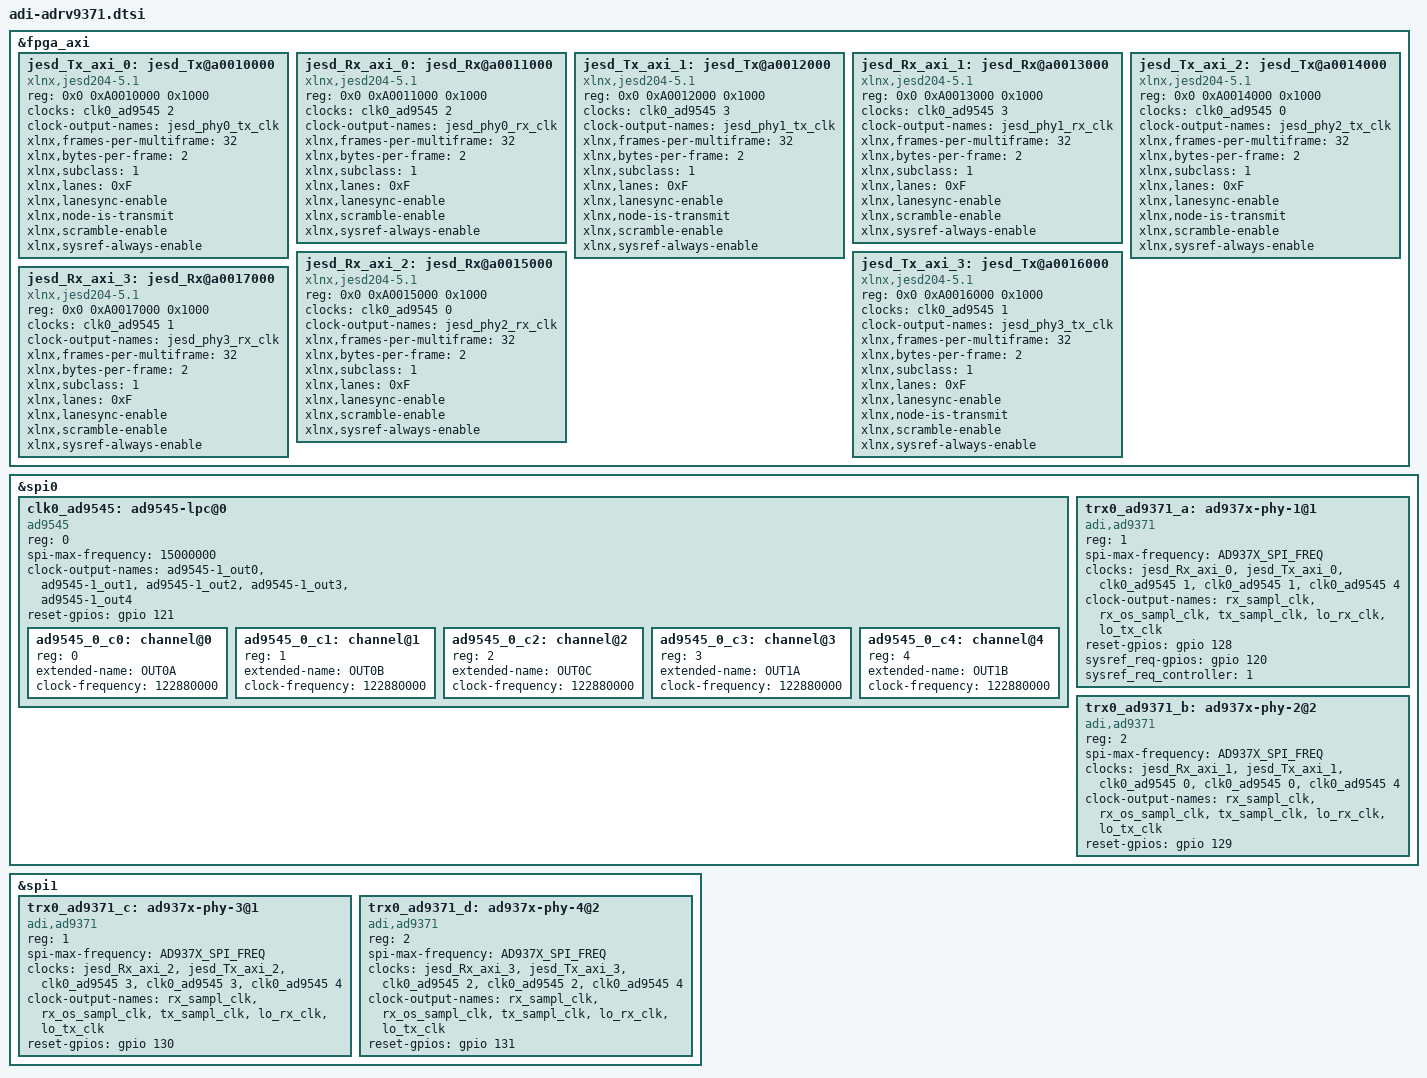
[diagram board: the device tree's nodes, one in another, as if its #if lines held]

#include <dt-bindings/iio/frequency/ad9528.h>

//#define USE_AD9545DRV_CFG_AD9528

&fpga_axi {
	//------------------------------
	//           1st
	//------------------------------
	// TO AD9371_A S1_REFCLKP  9528_C_13
	jesd_Tx_axi_0: jesd_Tx@a0010000 {
		#clock-cells = <0>;
		compatible = "xlnx,jesd204-5.1";
		reg = <0x0 0xA0010000 0x1000>;

#ifdef USE_AD9545DRV_CFG_AD9528
		clocks = <&clk0_ad9545 2>;
#else
		clocks = <&clk0_ad9528 4>;
#endif
		clock-names = "jesd_clk";
		clock-output-names = "jesd_phy0_tx_clk";

		xlnx,frames-per-multiframe = <32>;
		xlnx,bytes-per-frame = <2>;
		xlnx,subclass = <1>;
		xlnx,lanes = <0xF>;
		xlnx,lanesync-enable;
		xlnx,node-is-transmit;

		xlnx,scramble-enable;
		xlnx,sysref-always-enable;
	};
	jesd_Rx_axi_0: jesd_Rx@a0011000 {
		#clock-cells = <0>;
		compatible = "xlnx,jesd204-5.1";
		reg = <0x0 0xA0011000 0x1000>;

#ifdef USE_AD9545DRV_CFG_AD9528
		clocks = <&clk0_ad9545 2>;
#else
		clocks = <&clk0_ad9528 4>;
#endif
		clock-names = "jesd_clk";
		clock-output-names = "jesd_phy0_rx_clk";

		xlnx,frames-per-multiframe = <32>;
		xlnx,bytes-per-frame = <2>;
		xlnx,subclass = <1>;
		xlnx,lanes = <0xF>;
		xlnx,lanesync-enable;

		xlnx,scramble-enable;
		xlnx,sysref-always-enable;
	} ;
	//------------------------------
	//           2nd
	//------------------------------
	// TO AD9371_A S2_REFCLKP  9528_C_10
	jesd_Tx_axi_1: jesd_Tx@a0012000 {
		#clock-cells = <0>;
		compatible = "xlnx,jesd204-5.1";
		reg = <0x0 0xA0012000 0x1000>;

#ifdef USE_AD9545DRV_CFG_AD9528
		clocks = <&clk0_ad9545 3>;
#else
		clocks = <&clk0_ad9528 6>;
#endif
		clock-names = "jesd_clk";
		clock-output-names = "jesd_phy1_tx_clk";

		xlnx,frames-per-multiframe = <32>;
		xlnx,bytes-per-frame = <2>;
		xlnx,subclass = <1>;
		xlnx,lanes = <0xF>;
		xlnx,lanesync-enable;
		xlnx,node-is-transmit;

		xlnx,scramble-enable;
		xlnx,sysref-always-enable;
	};
	jesd_Rx_axi_1: jesd_Rx@a0013000 {
		#clock-cells = <0>;
		compatible = "xlnx,jesd204-5.1";
		reg = <0x0 0xA0013000 0x1000>;

#ifdef USE_AD9545DRV_CFG_AD9528
		clocks = <&clk0_ad9545 3>;
#else
		clocks = <&clk0_ad9528 6>;
#endif
		clock-names = "jesd_clk";
		clock-output-names = "jesd_phy1_rx_clk";

		xlnx,frames-per-multiframe = <32>;
		xlnx,bytes-per-frame = <2>;
		xlnx,subclass = <1>;
		xlnx,lanes = <0xF>;
		xlnx,lanesync-enable;

		xlnx,scramble-enable;
		xlnx,sysref-always-enable;
	} ;

	//------------------------------
	//           3rd
	//------------------------------
	// TO AD9371_C S3_REFCLKP  9528_C_8
	jesd_Tx_axi_2: jesd_Tx@a0014000 {
		#clock-cells = <0>;
		compatible = "xlnx,jesd204-5.1";
		reg = <0x0 0xA0014000 0x1000>;

#ifdef USE_AD9545DRV_CFG_AD9528
		clocks = <&clk0_ad9545 0>;
#else
		clocks = <&clk0_ad9528 1>;
#endif
		clock-names = "jesd_clk";
		clock-output-names = "jesd_phy2_tx_clk";

		xlnx,frames-per-multiframe = <32>;
		xlnx,bytes-per-frame = <2>;
		xlnx,subclass = <1>;
		xlnx,lanes = <0xF>;
		xlnx,lanesync-enable;
		xlnx,node-is-transmit;

		xlnx,scramble-enable;
		xlnx,sysref-always-enable;
	};
	jesd_Rx_axi_2: jesd_Rx@a0015000 {
		#clock-cells = <0>;
		compatible = "xlnx,jesd204-5.1";
		reg = <0x0 0xA0015000 0x1000>;

#ifdef USE_AD9545DRV_CFG_AD9528
		clocks = <&clk0_ad9545 0>;
#else
		clocks = <&clk0_ad9528 1>;
#endif
		clock-names = "jesd_clk";
		clock-output-names = "jesd_phy2_rx_clk";

		xlnx,frames-per-multiframe = <32>;
		xlnx,bytes-per-frame = <2>;
		xlnx,subclass = <1>;
		xlnx,lanes = <0xF>;
		xlnx,lanesync-enable;

		xlnx,scramble-enable;
		xlnx,sysref-always-enable;
	} ;
	//------------------------------
	//           4th
	//------------------------------
	// TO AD9371_D S3_REFCLKP  9528_C_8
	jesd_Tx_axi_3: jesd_Tx@a0016000 {
		#clock-cells = <0>;
		compatible = "xlnx,jesd204-5.1";
		reg = <0x0 0xA0016000 0x1000>;

#ifdef USE_AD9545DRV_CFG_AD9528
		clocks = <&clk0_ad9545 1>;
#else
		clocks = <&clk0_ad9528 3>;
#endif
		clock-names = "jesd_clk";
		clock-output-names = "jesd_phy3_tx_clk";

		xlnx,frames-per-multiframe = <32>;
		xlnx,bytes-per-frame = <2>;
		xlnx,subclass = <1>;
		xlnx,lanes = <0xF>;
		xlnx,lanesync-enable;
		xlnx,node-is-transmit;

		xlnx,scramble-enable;
		xlnx,sysref-always-enable;
	};
	jesd_Rx_axi_3: jesd_Rx@a0017000 {
		#clock-cells = <0>;
		compatible = "xlnx,jesd204-5.1";
		reg = <0x0 0xA0017000 0x1000>;

#ifdef USE_AD9545DRV_CFG_AD9528
		clocks = <&clk0_ad9545 1>;
#else
		clocks = <&clk0_ad9528 3>;
#endif
		clock-names = "jesd_clk";
		clock-output-names = "jesd_phy3_rx_clk";

		xlnx,frames-per-multiframe = <32>;
		xlnx,bytes-per-frame = <2>;
		xlnx,subclass = <1>;
		xlnx,lanes = <0xF>;
		xlnx,lanesync-enable;

		xlnx,scramble-enable;
		xlnx,sysref-always-enable;
	} ;

};

#define AD937X_SPI_FREQ 15000000

&spi0 {

#ifdef USE_AD9545DRV_CFG_AD9528
	/* 用9545的驱动按刷寄存器列表的方式初始化9528 */

	clk0_ad9545: ad9545-lpc@0 {
			#address-cells = <1>;
			#size-cells = <0>;
			#clock-cells = <1>;
			compatible = "ad9545";
			reg = <0>;

			//spi-3wire;
			spi-max-frequency = <15000000>;

			//reset-gpios = <&gpio_daq1 3 0>;

			clock-output-names = "ad9545-1_out0", "ad9545-1_out1", "ad9545-1_out2", "ad9545-1_out3", "ad9545-1_out4";

/include/ "ad9545map.dtsi"

			ad9545_0_c0:channel@0 {
				reg = <0>;
				extended-name = "OUT0A";
				clock-frequency = <122880000>;
			};
			ad9545_0_c1:channel@1 {
				reg = <1>;
				extended-name = "OUT0B";
				clock-frequency = <122880000>;

			};
			ad9545_0_c2:channel@2 {
				reg = <2>;
				extended-name = "OUT0C";
				clock-frequency = <122880000>;

			};
			ad9545_0_c3:channel@3 {
				reg = <3>;
				extended-name = "OUT1A";
				clock-frequency = <122880000>;

			};
			ad9545_0_c4:channel@4 {
				reg = <4>;
				extended-name = "OUT1B";
				clock-frequency = <122880000>;

			};
	};

#else		/* 用9545的驱动按刷寄存器列表的方式初始化9528 */

	clk0_ad9528: ad9528-1@0 {
			#address-cells = <1>;
			#size-cells = <0>;
			#clock-cells = <1>;
			compatible = "ad9528";

			spi-max-frequency = <15000000>;
			//adi,spi-3wire-enable;
			reg = <0>;

			clock-output-names = "ad9528-1_out0", "ad9528-1_out1", "ad9528-1_out2", "ad9528-1_out3", "ad9528-1_out4", "ad9528-1_out5", 	"ad9528-1_out6", "ad9528-1_out7", "ad9528-1_out8", "ad9528-1_out9", "ad9528-1_out10", "ad9528-1_out11", "ad9528-1_out12", 	"ad9528-1_out13";
#if defined (OSC_122M88)
			adi,vcxo-freq = <122880000>;
#elif defined (OSC_30M72)
			adi,vcxo-freq = <30720000>;
#endif
			adi,refa-enable=<1>;	// rj
			adi,refa-diff-rcv-enable=<1>;	//rj

#if defined (OSC_122M88)
            adi,refa-r-div = <8>;	// rj <32>;
#elif defined (OSC_30M72)
			adi,refa-r-div = <128>;
#endif
			//adi,osc-in-cmos-neg-inp-enable;

			adi,refb-r-div = <16>;	// rj

			/* PLL1 config */
			adi,pll1-feedback-div = <64>;	// <256>;

			adi,pll1-charge-pump-current-nA = <63500>;


			/* PLL2 config */
			adi,pll2-ndiv-a-cnt = <0>;
			adi,pll2-ndiv-b-cnt = <30>;
			adi,pll2-vco-diff-m1 = <3>; /* use 5 for 184320000 output device clock */
#if defined (OSC_122M88)
						adi,pll2-n2-div = <10>; /* N / M1 */
#elif defined (OSC_30M72)
						adi,pll2-n2-div = <40>; /* N / M1 */
#endif
			adi,pll2-r1-div = <1>;
			adi,pll2-charge-pump-current-nA = <805000>;

			adi,ref-mode=<REF_MODE_SELECT_REFB>;	// rj

			/* SYSREF config */
			adi,sysref-src = <SYSREF_SRC_INTERNAL>;
			adi,sysref-pattern-mode = <SYSREF_PATTERN_CONTINUOUS>;
			adi,sysref-k-div = <512>;
			adi,sysref-request-enable;
			adi,sysref-nshot-mode = <SYSREF_NSHOT_4_PULSES>;
			adi,sysref-request-trigger-mode = <SYSREF_LEVEL_HIGH>;

			adi,rpole2 = <RPOLE2_900_OHM>;
			adi,rzero = <RZERO_1850_OHM>;
			adi,cpole1 = <CPOLE1_16_PF>;

			adi,status-mon-pin0-function-select = <1>; /* PLL1 & PLL2 Locked */
			adi,status-mon-pin1-function-select = <7>; /* REFA Correct */

			ad9528_0_c0: channel@0 {
				reg = <0>;
				adi,extended-name = "C_AD9373_SYSREFCLK";
				adi,driver-mode = <DRIVER_MODE_LVDS>;
				adi,divider-phase = <0>;
				adi,channel-divider = <10>;
				adi,signal-source = <SOURCE_SYSREF_VCO>;
			};

			ad9528_0_c1: channel@1 {
				reg = <1>;
				adi,extended-name = "C_AD9373_DEVCLK";
				adi,driver-mode = <DRIVER_MODE_LVDS>;
				adi,divider-phase = <0>;
				adi,channel-divider = <1>;	// rj <10>;
				adi,signal-source = <SOURCE_VCXO>;	// rj <SOURCE_VCO>;
			};

			ad9528_0_c2: channel@2 {
				reg = <2>;
				adi,extended-name = "D_AD9373_SYSREFCLK";
				adi,driver-mode = <DRIVER_MODE_LVDS>;
				adi,divider-phase = <0>;
				adi,channel-divider = <10>;
				adi,signal-source = <SOURCE_SYSREF_VCO>;
			};

			ad9528_0_c3: channel@3 {
				reg = <3>;
				adi,extended-name = "D_AD9373_DEVCLK";
				adi,driver-mode = <DRIVER_MODE_LVDS>;
				adi,divider-phase = <0>;
				adi,channel-divider = <1>;	// rj <10>;
				adi,signal-source = <SOURCE_VCXO>;	// rj <SOURCE_VCO>;
			};
			ad9528_0_c4: channel@4 {
				reg = <4>;
				adi,extended-name = "A_AD9373_DEVCLK";
				adi,driver-mode = <DRIVER_MODE_LVDS>;
				adi,divider-phase = <0>;
				adi,channel-divider = <1>;	// rj <10>;
				adi,signal-source = <SOURCE_VCXO>;	// rj <SOURCE_VCO>;
			};

			ad9528_0_c5: channel@5 {
				reg = <5>;
				adi,extended-name = "A_AD9373_SYSREFCLK";
				adi,driver-mode = <DRIVER_MODE_LVDS>;
				adi,divider-phase = <0>;
				adi,channel-divider = <10>;
				adi,signal-source = <SOURCE_SYSREF_VCO>;
			};

			ad9528_0_c6: channel@6 {
				reg = <6>;
				adi,extended-name = "B_AD9373_DEVCLK";
				adi,driver-mode = <DRIVER_MODE_LVDS>;
				adi,divider-phase = <0>;
				adi,channel-divider = <1>;	// rj <10>;
				adi,signal-source = <SOURCE_VCXO>;	// rj <SOURCE_VCO>;
			};

			ad9528_0_c7: channel@7 {
				reg = <7>;
				adi,extended-name = "B_AD9373_SYSREFCLK";
				adi,driver-mode = <DRIVER_MODE_LVDS>;
				adi,divider-phase = <0>;
				adi,channel-divider = <10>;
				adi,signal-source = <SOURCE_SYSREF_VCO>;
			};
			ad9528_0_c8: channel@8 {
				reg = <8>;
				adi,extended-name = "S3_REFCLKP";
				adi,driver-mode = <DRIVER_MODE_LVDS>;
				adi,divider-phase = <0>;
				adi,channel-divider = <10>;
				adi,signal-source = <SOURCE_VCO>;
			};

			ad9528_0_c9: channel@9 {
				reg = <9>;
				adi,extended-name = "S4_REFCLKP";
				adi,driver-mode = <DRIVER_MODE_LVDS>;
				adi,divider-phase = <0>;
				adi,channel-divider = <8>;
				adi,signal-source = <SOURCE_VCO>;
			};

			ad9528_0_c10: channel@10 {
				reg = <10>;
				adi,extended-name = "S2_REFCLKP";
				adi,driver-mode = <DRIVER_MODE_LVDS>;
				adi,divider-phase = <0>;
				adi,channel-divider = <10>;
				adi,signal-source = <SOURCE_VCO>;
			};

			ad9528_0_c11: channel@11 {
				reg = <11>;
				adi,extended-name = "S5_REFCLKP";
				adi,driver-mode = <DRIVER_MODE_LVDS>;
				adi,divider-phase = <0>;
				adi,channel-divider = <10>;
				adi,signal-source = <SOURCE_VCO>;
			};

			ad9528_0_c12: channel@12 {
				reg = <12>;
				adi,extended-name = "FPGA_SYSREFCLK1";
				adi,driver-mode = <DRIVER_MODE_LVDS>;
				adi,divider-phase = <0>;
				adi,channel-divider = <10>;
				adi,signal-source = <SOURCE_SYSREF_VCO>;
			};

			ad9528_0_c13: channel@13 {
				reg = <13>;
				adi,extended-name = "S1_REFCLKP";
				adi,driver-mode = <DRIVER_MODE_LVDS>;
				adi,divider-phase = <0>;
				adi,channel-divider = <10>;
				adi,signal-source = <SOURCE_VCO>;
			};
	};
#endif	/* 用9545的驱动按刷寄存器列表的方式初始化9528 */

/* trx0_ad9371_c  jesd_rx_os_clk,dev_clk： clk0_ad9528 1		clk0_ad9545 0*/
/* trx0_ad9371_d  jesd_rx_os_clk,dev_clk： clk0_ad9528 3		clk0_ad9545 1*/
/* trx0_ad9371_a  jesd_rx_os_clk,dev_clk:   clk0_ad9528 4		clk0_ad9545 2*/
/* trx0_ad9371_b  jesd_rx_os_clk,dev_clk:   clk0_ad9528 6		clk0_ad9545 3*/
/* trx0_ad9371_*  fmc_clk:                  clk0_ad9528 11		clk0_ad9545 4*/


	trx0_ad9371_a: ad937x-phy-1@1 {
		compatible = "adi,ad9371";
		reg = <1>;
		/* SPI Setup */
		spi-max-frequency = <AD937X_SPI_FREQ>;

		/* Clocks */
#ifdef USE_AD9545DRV_CFG_AD9528
		clocks = <&jesd_Rx_axi_0>, <&jesd_Tx_axi_0>, <&clk0_ad9545 1>, <&clk0_ad9545 1>, <&clk0_ad9545 4>;
#else
		clocks = <&jesd_Rx_axi_0>, <&jesd_Tx_axi_0>, <&clk0_ad9528 4>, <&clk0_ad9528 4>, <&clk0_ad9528 11>;
#endif
		clock-names = "jesd_rx_clk", "jesd_tx_clk","jesd_rx_os_clk", "dev_clk", "fmc_clk";

		clock-output-names = "rx_sampl_clk", "rx_os_sampl_clk", "tx_sampl_clk","lo_rx_clk","lo_tx_clk";
		#clock-cells = <1>;

		/include/ "ad9371_mux.dtsi"
	};

	trx0_ad9371_b: ad937x-phy-2@2 {
		compatible = "adi,ad9371";
		reg = <2>;
		/* SPI Setup */
		spi-max-frequency = <AD937X_SPI_FREQ>;

		/* Clocks */
#ifdef USE_AD9545DRV_CFG_AD9528
		clocks = <&jesd_Rx_axi_1>, <&jesd_Tx_axi_1>, <&clk0_ad9545 0>, <&clk0_ad9545 0>, <&clk0_ad9545 4>;
#else
		clocks = <&jesd_Rx_axi_1>, <&jesd_Tx_axi_1>, <&clk0_ad9528 6>, <&clk0_ad9528 6>, <&clk0_ad9528 11>;
#endif
		clock-names = "jesd_rx_clk", "jesd_tx_clk","jesd_rx_os_clk", "dev_clk", "fmc_clk";

		clock-output-names = "rx_sampl_clk", "rx_os_sampl_clk", "tx_sampl_clk","lo_rx_clk","lo_tx_clk";
		#clock-cells = <1>;

		/include/ "ad9371_mux.dtsi"
	};

};

&spi1 {


	trx0_ad9371_c: ad937x-phy-3@1 {
		compatible = "adi,ad9371";
		reg = <1>;
		/* SPI Setup */
		spi-max-frequency = <AD937X_SPI_FREQ>;

		/* Clocks */
#ifdef USE_AD9545DRV_CFG_AD9528
		clocks = <&jesd_Rx_axi_2>, <&jesd_Tx_axi_2>, <&clk0_ad9545 3>, <&clk0_ad9545 3>, <&clk0_ad9545 4>;
#else
		clocks = <&jesd_Rx_axi_2>, <&jesd_Tx_axi_2>, <&clk0_ad9528 1>, <&clk0_ad9528 1>, <&clk0_ad9528 11>;
#endif
		clock-names = "jesd_rx_clk", "jesd_tx_clk","jesd_rx_os_clk", "dev_clk", "fmc_clk";

		clock-output-names = "rx_sampl_clk", "rx_os_sampl_clk", "tx_sampl_clk","lo_rx_clk","lo_tx_clk";
		#clock-cells = <1>;

		/include/ "ad9371_mux.dtsi"
	};

	trx0_ad9371_d: ad937x-phy-4@2 {
		compatible = "adi,ad9371";
		reg = <2>;
		/* SPI Setup */
		spi-max-frequency = <AD937X_SPI_FREQ>;

		/* Clocks */
#ifdef USE_AD9545DRV_CFG_AD9528
		clocks = <&jesd_Rx_axi_3>, <&jesd_Tx_axi_3>, <&clk0_ad9545 2>, <&clk0_ad9545 2>, <&clk0_ad9545 4>;
#else
		clocks = <&jesd_Rx_axi_3>, <&jesd_Tx_axi_3>, <&clk0_ad9528 3>, <&clk0_ad9528 3>, <&clk0_ad9528 11>;
#endif
		clock-names = "jesd_rx_clk", "jesd_tx_clk","jesd_rx_os_clk", "dev_clk", "fmc_clk";

		clock-output-names = "rx_sampl_clk", "rx_os_sampl_clk", "tx_sampl_clk","lo_rx_clk","lo_tx_clk";
		#clock-cells = <1>;

		/include/ "ad9371_mux.dtsi"
	};

};

//-------------------------------------------------------------------------------------------

&trx0_ad9371_d {
	reset-gpios = <&gpio 131 0>; //50
	//test-gpios = <&gpio0 107 0>;
//	sysref_req-gpios = <&gpio 112 0>; //58
	//rx2_enable-gpios = <&gpio0 108 0>;
	//rx1_enable-gpios = <&gpio0 109 0>;
	//tx2_enable-gpios = <&gpio0 110 0>;
	//tx1_enable-gpios = <&gpio0 111 0>;
};

&trx0_ad9371_c {
	reset-gpios = <&gpio 130 0>;
//	sysref_req-gpios = <&gpio 113 0>;
};

&trx0_ad9371_b {
	reset-gpios = <&gpio 129 0>;
//	sysref_req-gpios = <&gpio 114 0>;
};


&trx0_ad9371_a {
	reset-gpios = <&gpio 128 0>;
	sysref_req-gpios = <&gpio 120 0>;
	sysref_req_controller=<1>;
};


#ifdef USE_AD9545DRV_CFG_AD9528
&clk0_ad9545 {
#else
&clk0_ad9528 {
#endif
	reset-gpios = <&gpio 121 0>;
};


// ad9371_dac_fifo_bypass_s 60
// ad9528_reset_b,       // 59
// ad9528_sysref_req,    // 58
// ad9371_tx1_enable,    // 57
// ad9371_tx2_enable,    // 56
// ad9371_rx1_enable,    // 55
// ad9371_rx2_enable,    // 54
// ad9371_test,          // 53
// ad9371_reset_b,       // 52
// ad9371_gpint,         // 51
// ad9371_gpio_00,       // 50
// ad9371_gpio_01,       // 49
// ad9371_gpio_02,       // 48
// ad9371_gpio_03,       // 47
// ad9371_gpio_04,       // 46
// ad9371_gpio_05,       // 45
// ad9371_gpio_06,       // 44
// ad9371_gpio_07,       // 43
// ad9371_gpio_15,       // 42
// ad9371_gpio_08,       // 41
// ad9371_gpio_09,       // 40
// ad9371_gpio_10,       // 39
// ad9371_gpio_11,       // 38
// ad9371_gpio_12,       // 37
// ad9371_gpio_14,       // 36
// ad9371_gpio_13,       // 35
// ad9371_gpio_17,       // 34
// ad9371_gpio_16,       // 33
// ad9371_gpio_18}));    // 32 + 54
